# LPC55S06 register map
Vendor: nxp.com; File version: 1.0
CPU: CM33 r2p0, little endian, MPU, FPU, VTOR, 3 interrupt priority bits
Registers are 32-bit, read-write, reset 0x0 unless marked. A register's access mark holds for its fields unless they carry their own. Offsets are from the block's base; [hi:lo] are bit positions; {n}, {i} and the like mark numbered series; 'fields as' and 'values as' point back to an identical list.

## FLASH_NMPA
Base 0x0003FC00
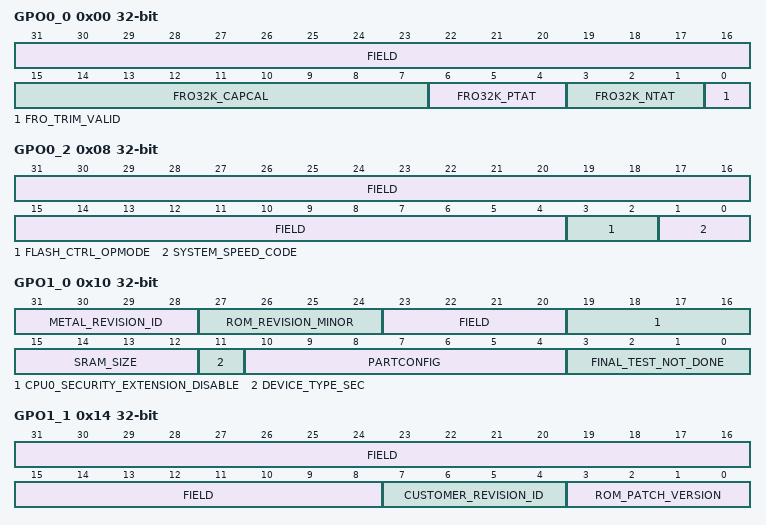
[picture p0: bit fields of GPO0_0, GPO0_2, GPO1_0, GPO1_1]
0x00 GPO0_0 (GPO0 view) — GPO0 register 0 description
  [31:16] FIELD, [15:7] FRO32K_CAPCAL, [6:4] FRO32K_PTAT, [3:1] FRO32K_NTAT, [0] FRO_TRIM_VALID
{0x0+0x10*i} GPO{i}_ARRAY0 (GPO{i} view) (i=0..3) — GPO{i} array description
  [31:0] FIELD
0x04 GPO0_1 (GPO0 view) — GPO0 register 1 description
  [31:0] FIELD
{0x4+0x10*i} GPO{i}_ARRAY1 (GPO{i} view) (i=0..3) — GPO{i} array description
  [31:0] FIELD
0x08 GPO0_2 (GPO0 view) — GPO0 register 2 description
  [31:4] FIELD
  [3:2] FLASH_CTRL_OPMODE — 00 : Delay Line 01 : RCLK (back up clock) 10 : PCLK (back up clock)
  [1:0] SYSTEM_SPEED_CODE — 00 : FRO12MHz 01 : FRO24MHz 10 : FRO48MHz 11 : FRO96MHz
{0x8+0x10*i} GPO{i}_ARRAY2 (GPO{i} view) (i=0..3) — GPO{i} array description
  [31:0] FIELD
0x0C GPO0_3 (GPO0 view) — GPO0 register 3 description
  [31:0] FIELD
{0xC+0x10*i} GPO{i}_ARRAY3 (GPO{i} view) (i=0..3) — GPO{i} array description
  [31:0] FIELD
0x10 GPO1_0 (GPO1 view) — GPO1 register 0 description
  [31:28] METAL_REVISION_ID — METAL REVISION ID[3:0]
  [27:24] ROM_REVISION_MINOR — ROM Revision-Minor [3:0]
  [23:20] FIELD
  [19:16] CPU0_SECURITY_EXTENSION_DISABLE — CPU0_SECURITY_EXTENSION_DISABLE[3:0]: 1010 : CPU0 Security Extension is disabled. All Other values: CPU0 Security Extension is enabled.
  [15:12] SRAM_SIZE — SRAM_SIZE[3:0]: (For Niobe4) 0000 : 320 KB 0001 : 256 KB 0010 : 144 KB 0011 : 80 KB (For Niobe4 Mini) 0100 : 96 KB 0101 : 80 KB 0110 : 64 KB 0111 : 48 KB All others : RESERVED
  [11] DEVICE_TYPE_SEC — Security device type: 0: LPC55xxx (Non Secure Familly) 1: LPC55Sxxx (Secure Familly)
  [10:4] PARTCONFIG — Device type number. (E.g : LPC5569 stored as 69 decimal)
  [3:0] FINAL_TEST_NOT_DONE — FINAL_TEST_NOT_DONE[3:0]: 1010 : Final Test Not Done. All Other values: Final Test Done.
0x14 GPO1_1 (GPO1 view) — GPO1 register 1 description
  [31:8] FIELD
  [7:4] CUSTOMER_REVISION_ID — CUSTOMER REVISION ID[3:0]
  [3:0] ROM_PATCH_VERSION — ROM Patch Version [3:0]
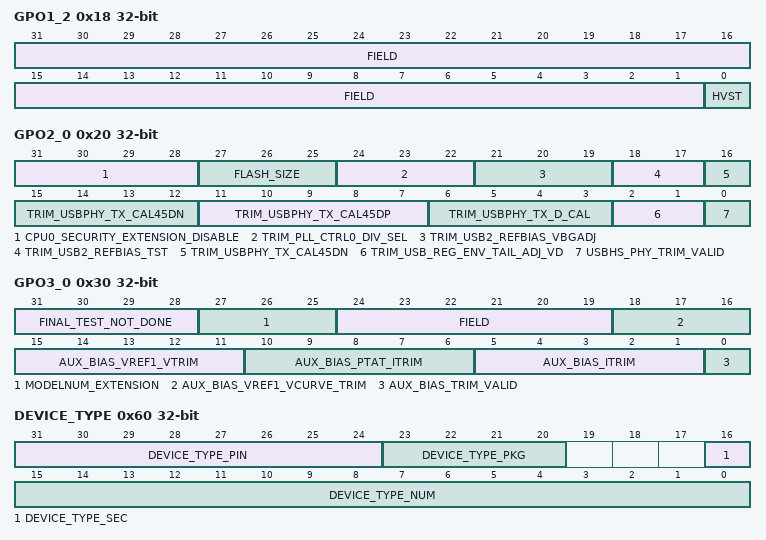
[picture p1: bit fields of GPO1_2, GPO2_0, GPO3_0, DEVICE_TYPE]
0x18 GPO1_2 (GPO1 view) — GPO1 register 2 description
  [31:1] FIELD
  [0] HVST — High Voltage Stress: 0=not done; 1=done.
0x1C GPO1_3 (GPO1 view) — GPO1 register 3 description
  [31:0] FIELD
0x20 GPO2_0 (GPO2 view) — GPO2 register 0 description
  [31:28] CPU0_SECURITY_EXTENSION_DISABLE — CPU0_SECURITY_EXTENSION_DISABLE[3:0]: 1010 : CPU0 Security Extension is disabled. All Other values: CPU0 Security Extension is enabled.
  [27:25] FLASH_SIZE — (For Niobe4) 000 : 640 KB 001 : 512 KB 010 : 256 KB 011 : 128 KB 100 : 0 KB All others : RESERVED (For Niobe4 Mini) FLASH_SIZE[2:0] 000 : 256 KB 001 : 128 KB 010 : 80 KB (reserved) 011 : 64 KB 100 : 0 kB (reserved) All others : RESERVED
  [24:22] TRIM_PLL_CTRL0_DIV_SEL
  [21:19] TRIM_USB2_REFBIAS_VBGADJ
  [18:17] TRIM_USB2_REFBIAS_TST
  [16:12] TRIM_USBPHY_TX_CAL45DN
  [11:7] TRIM_USBPHY_TX_CAL45DP
  [6:3] TRIM_USBPHY_TX_D_CAL
  [2:1] TRIM_USB_REG_ENV_TAIL_ADJ_VD
  [0] USBHS_PHY_TRIM_VALID
{0x20+4i} GPO2_{i} (GPO2 view) (i=1..3) — GPO2 register {i} description
  [31:0] FIELD
0x30 GPO3_0 (GPO3 view) — GPO3 register 0 description
  [31:28] FINAL_TEST_NOT_DONE — FINAL_TEST_NOT_DONE[3:0]: 1010 : Final Test Not Done. All Other values: Final Test Done.
  [27:25] MODELNUM_EXTENSION — ModelNumber extension[2:0]
  [24:19] FIELD
  [18:16] AUX_BIAS_VREF1_VCURVE_TRIM
  [15:11] AUX_BIAS_VREF1_VTRIM
  [10:6] AUX_BIAS_PTAT_ITRIM
  [5:1] AUX_BIAS_ITRIM
  [0] AUX_BIAS_TRIM_VALID
{0x30+4i} GPO3_{i} (GPO3 view) (i=1..3) — GPO3 register {i} description
  [31:0] FIELD
{0x40+4i} GPO_CHECKSUM_{i} (GPO_CHECKSUM view) (i=0..3) — checksum of the GPO data in words {i}
  [31:0] FIELD
{0x40+4i} GPO_CHECKSUM_ARRAY{i} (GPO_CHECKSUM view) (i=0..3) — checksum of the GPO data in words [3:0]
  [31:0] FIELD
{0x50+4i} FINAL_TEST_BATCH_ID_{i} (FINAL_TEST_BATCH_ID view) (i=0..3)
  [31:0] FIELD
{0x50+4i} FINAL_TEST_BATCH_ID_ARRAY{i} (FINAL_TEST_BATCH_ID view) (i=0..3)
  [31:0] FIELD
0x60 DEVICE_TYPE
  [31:24] DEVICE_TYPE_PIN — Number of pins on the package.
  [23:20] DEVICE_TYPE_PKG — Device package type: 0000 : HLQFP 0001 : HTQFP 0010 : HVQFN 0100 : VFBGA 1000 : WLCSP
  [16] DEVICE_TYPE_SEC — Security device type: 0: LPC55xxx (Non Secure Familly) 1: LPC55Sxxx (Secure Familly)
  [15:0] DEVICE_TYPE_NUM — Device type number. (E.g : LPC5569 stored as 5569 decimal)
0x64 FINAL_TEST_PROGRAM_VERSION
  [31:0] PROGRAM_VERSION — PROGRAM_VERSION [xx.yy stored as : 100*x+y]
0x68 FINAL_TEST_DATE
  [31:0] DATE — DATE [stored as : year*10000+month*100+day]
0x6C FINAL_TEST_TIME
  [31:0] TIME — TIME [stored as : hour*10000+minute*100+seconde]
{0x70+4i} UUID_{i} (UUID view) (i=0..3)
  [31:0] FIELD
{0x70+4i} UUID_ARRAY{i} (UUID view) (i=0..3)
  [31:0] FIELD
0x80 WAFER_TEST1_PROGRAM_VERSION
  [31:0] WT1_PROGRAM_VERSION — WT1_PROGRAM_VERSION [xx.yy stored as : 100*x+y]
0x84 WAFER_TEST1_DATE
  [31:0] WT1_DATE — WT1_DATE [stored as : year*10000+month*100+day]
0x88 WAFER_TEST1_TIME
  [31:0] WT1_TIME — WT1_TIME [stored as : hour*10000+minute*100+seconde]
0x90 WAFER_TEST2_PROGRAM_VERSION
  [31:0] WT2_PROGRAM_VERSION — WT2_PROGRAM_VERSION [xx.yy stored as : 100*x+y]
0x94 WAFER_TEST2_DATE
  [31:0] WT2_DATE — WT2_DATE [stored as : year*10000+month*100+day]
0x98 WAFER_TEST2_TIME
  [31:0] WT2_TIME — WT2_TIME [stored as : hour*10000+minute*100+seconde]
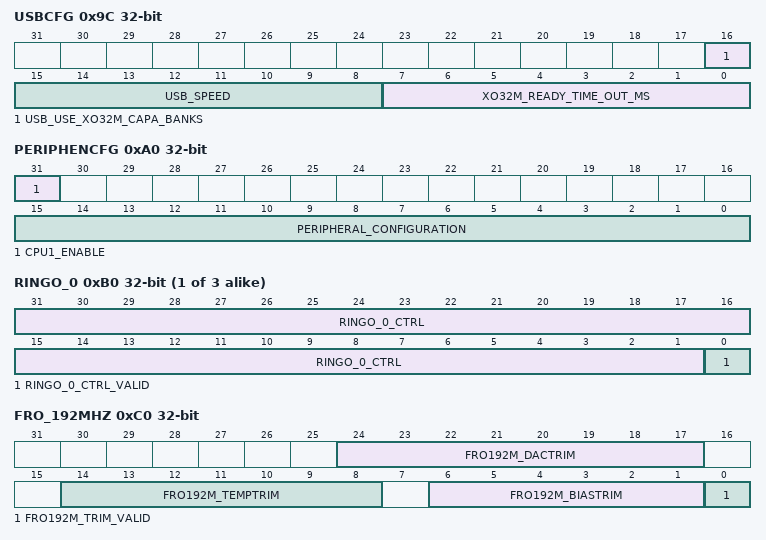
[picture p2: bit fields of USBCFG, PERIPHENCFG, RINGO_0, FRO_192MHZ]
0x9C USBCFG
  [16] USB_USE_XO32M_CAPA_BANKS — Enable the use of Crystal 32 MHz internal Capa Banks during the configuration of the High Speed USB for ISP: 0: Disable Crystal 32 MHz CapaBanks. 1: Enable Crystal 32 MHz CapaBanks.
  [15:8] USB_SPEED — USB_SPEED[7:0]= 0x00 : USB High Speed Module used for ISP 0x01 : USB Full SPeed Module used for ISP 0x02 : Neither USB High Speed module nor USB Full Speed module used for ISP 0x03 - 0xFF : RESERVED
  [7:0] XO32M_READY_TIME_OUT_MS
0xA0 PERIPHENCFG
  [31] CPU1_ENABLE, [15:0] PERIPHERAL_CONFIGURATION
0xA4 RAMSIZECFG
  [31:0] SRAM_CONFIGURATION
0xA8 FLASHSIZECFG
  [31:0] FLASH_CONFIGURATION
{0xB0+4i} RINGO_{i} (i=0..2)
  [31:1] RINGO_{i}_CTRL — To copy RINGO_{i}_CTRL = ANACTRL->RINGO{i}_CTRL[30:0]
  [0] RINGO_{i}_CTRL_VALID — 1: RINGO_{i}_CTRL is valid.
0xC0 FRO_192MHZ
  [24:17] FRO192M_DACTRIM — FRO192M_DACTRIM[7:0].
  [14:8] FRO192M_TEMPTRIM — FRO192M_TEMPTRIM[6:0].
  [6:1] FRO192M_BIASTRIM — FRO192M_BIASTRIM[5:0].
  [0] FRO192M_TRIM_VALID
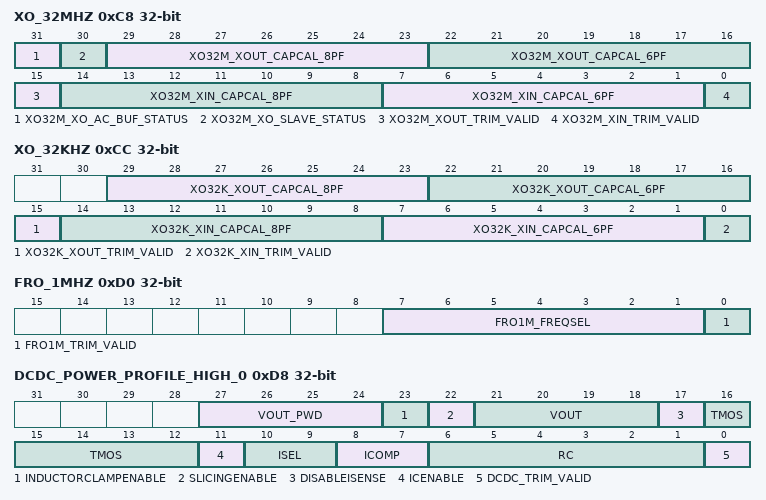
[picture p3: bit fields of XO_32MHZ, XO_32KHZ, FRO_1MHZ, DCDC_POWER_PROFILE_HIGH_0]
0xC8 XO_32MHZ
  [31] XO32M_XO_AC_BUF_STATUS, [30] XO32M_XO_SLAVE_STATUS, [29:23] XO32M_XOUT_CAPCAL_8PF, [22:16] XO32M_XOUT_CAPCAL_6PF, [15] XO32M_XOUT_TRIM_VALID, [14:8] XO32M_XIN_CAPCAL_8PF, [7:1] XO32M_XIN_CAPCAL_6PF, [0] XO32M_XIN_TRIM_VALID
0xCC XO_32KHZ
  [29:23] XO32K_XOUT_CAPCAL_8PF, [22:16] XO32K_XOUT_CAPCAL_6PF, [15] XO32K_XOUT_TRIM_VALID, [14:8] XO32K_XIN_CAPCAL_8PF, [7:1] XO32K_XIN_CAPCAL_6PF, [0] XO32K_XIN_TRIM_VALID
0xD0 FRO_1MHZ
  [7:1] FRO1M_FREQSEL — Frequency trimming bits.
  [0] FRO1M_TRIM_VALID
0xD8 DCDC_POWER_PROFILE_HIGH_0 (DCDC_POWER_PROFILE_HIGH view)
  [27:24] VOUT_PWD — Set output regulation voltage during Deep Sleep.
  [23] INDUCTORCLAMPENABLE — Enable shorting of Inductor during PFM idle time.
  [22] SLICINGENABLE — Enable staggered switching of power switches.
  [21:18] VOUT — Set output regulation voltage.
  [17] DISABLEISENSE — Disable Current sensing.
  [16:12] TMOS — One-shot generator reference current trimming signal.
  [11] ICENABLE — Selection of auto scaling of COT period with variations in VDD.
  [10:9] ISEL — Alter Internal biasing currents.
  [8:7] ICOMP — Select the type of ZCD comparator.
  [6:1] RC — Constant On-Time calibration.
  [0] DCDC_TRIM_VALID — DCDC is trimed.
0xD8 DCDC_POWER_PROFILE_HIGH_ARRAY0 (DCDC_POWER_PROFILE_HIGH view)
  [31:0] FIELD
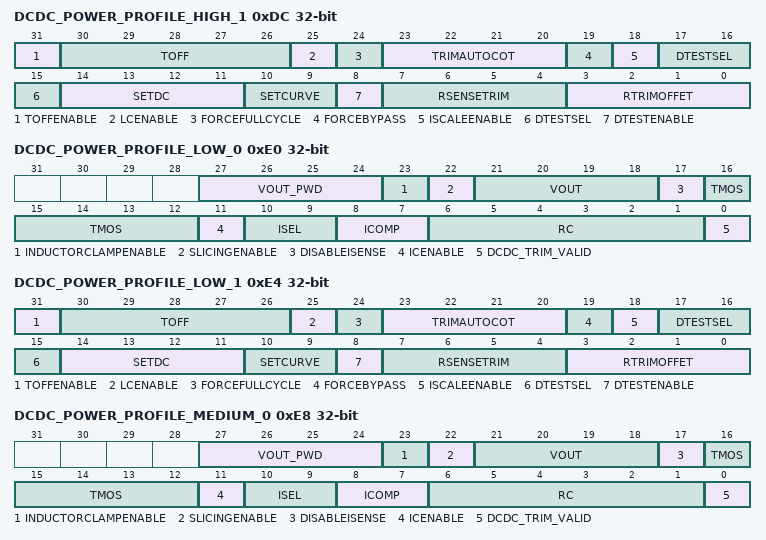
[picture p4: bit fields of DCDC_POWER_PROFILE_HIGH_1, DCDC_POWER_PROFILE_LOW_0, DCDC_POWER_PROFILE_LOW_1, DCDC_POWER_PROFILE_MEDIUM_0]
0xDC DCDC_POWER_PROFILE_HIGH_1 (DCDC_POWER_PROFILE_HIGH view)
  [31] TOFFENABLE — Enable Constant Off-Time feature.
  [30:26] TOFF — Constant Off-Time calibration input.
  [25] LCENABLE — Change the range of the peak detector of current inside the inductor.
  [24] FORCEFULLCYCLE — Force full PFM PMOS and NMOS cycle.
  [23:20] TRIMAUTOCOT — Change the scaling ratio of the feedforward compensation.
  [19] FORCEBYPASS — Force bypass mode.
  [18] ISCALEENABLE — Modify COT behavior.
  [17:15] DTESTSEL — Select the output signal for test.
  [14:11] SETDC — Bandgap calibration parameter.
  [10:9] SETCURVE — Bandgap calibration parameter.
  [8] DTESTENABLE — Enable Digital test signals.
  [7:4] RSENSETRIM — Adjust Max inductor peak current limiting.
  [3:0] RTRIMOFFET — Adjust the offset voltage of BJT based comparator.
0xDC DCDC_POWER_PROFILE_HIGH_ARRAY1 (DCDC_POWER_PROFILE_HIGH view)
  [31:0] FIELD
0xE0 DCDC_POWER_PROFILE_LOW_0 (DCDC_POWER_PROFILE_LOW view)
  fields as DCDC_POWER_PROFILE_HIGH_0
0xE0 DCDC_POWER_PROFILE_LOW_ARRAY0 (DCDC_POWER_PROFILE_LOW view)
  [31:0] FIELD
0xE4 DCDC_POWER_PROFILE_LOW_1 (DCDC_POWER_PROFILE_LOW view)
  fields as DCDC_POWER_PROFILE_HIGH_1
0xE4 DCDC_POWER_PROFILE_LOW_ARRAY1 (DCDC_POWER_PROFILE_LOW view)
  [31:0] FIELD
0xE8 DCDC_POWER_PROFILE_MEDIUM_0 (DCDC_POWER_PROFILE_MEDIUM view)
  fields as DCDC_POWER_PROFILE_HIGH_0
0xE8 DCDC_POWER_PROFILE_MEDIUM_ARRAY0 (DCDC_POWER_PROFILE_MEDIUM view)
  [31:0] FIELD
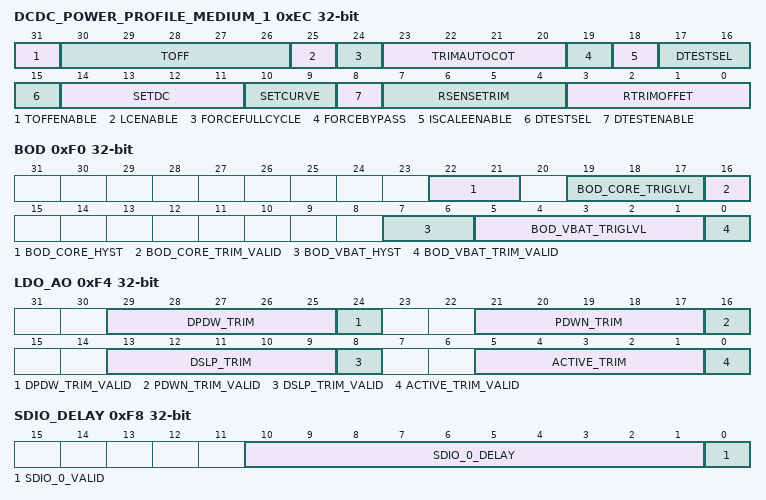
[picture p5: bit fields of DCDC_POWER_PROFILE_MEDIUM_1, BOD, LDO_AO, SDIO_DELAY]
0xEC DCDC_POWER_PROFILE_MEDIUM_1 (DCDC_POWER_PROFILE_MEDIUM view)
  fields as DCDC_POWER_PROFILE_HIGH_1
0xEC DCDC_POWER_PROFILE_MEDIUM_ARRAY1 (DCDC_POWER_PROFILE_MEDIUM view)
  [31:0] FIELD
0xF0 BOD
  [22:21] BOD_CORE_HYST, [19:17] BOD_CORE_TRIGLVL, [16] BOD_CORE_TRIM_VALID, [7:6] BOD_VBAT_HYST, [5:1] BOD_VBAT_TRIGLVL, [0] BOD_VBAT_TRIM_VALID
0xF4 LDO_AO
  [29:25] DPDW_TRIM, [24] DPDW_TRIM_VALID, [21:17] PDWN_TRIM, [16] PDWN_TRIM_VALID, [13:9] DSLP_TRIM, [8] DSLP_TRIM_VALID, [5:1] ACTIVE_TRIM, [0] ACTIVE_TRIM_VALID
0xF8 SDIO_DELAY
  [10:1] SDIO_0_DELAY — SDIO_0_DELAY (unit: 100 ps).
  [0] SDIO_0_VALID
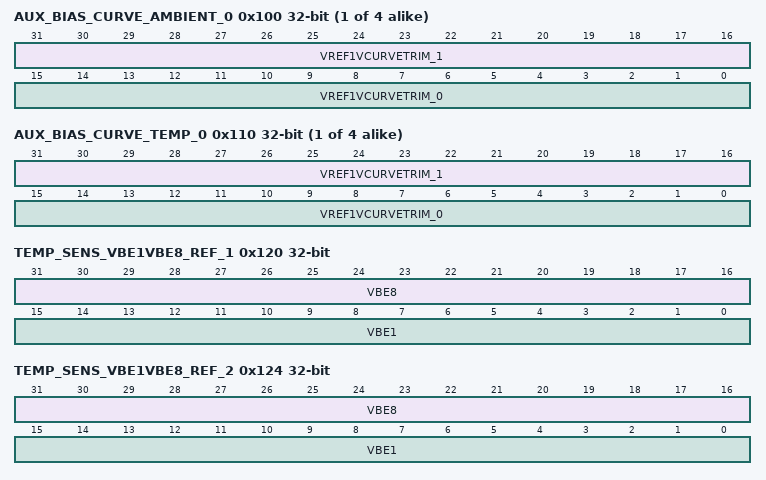
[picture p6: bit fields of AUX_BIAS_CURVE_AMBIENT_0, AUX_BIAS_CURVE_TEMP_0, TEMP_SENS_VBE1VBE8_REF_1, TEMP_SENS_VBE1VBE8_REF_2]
{0x100+4i} AUX_BIAS_CURVE_AMBIENT_{i} (AUX_BIAS_CURVE_AMBIENT view) (i=0..3)
  [31:16] VREF1VCURVETRIM_{2i+1} — VREF1VCURVETRIM_{2i+1} (unit: 100uV)
  [15:0] VREF1VCURVETRIM_{2i} — VREF1VCURVETRIM_{2i} (unit: 100uV)
{0x100+4i} AUX_BIAS_CURVE_AMBIENT_ARRAY{i} (AUX_BIAS_CURVE_AMBIENT view) (i=0..3) — Aux Bias Curve Ambient (30degC)
  [31:0] FIELD
{0x110+4i} AUX_BIAS_CURVE_TEMP_{i} (AUX_BIAS_CURVE_TEMP view) (i=0..3)
  fields as AUX_BIAS_CURVE_AMBIENT_0
{0x110+4i} AUX_BIAS_CURVE_TEMP_ARRAY{i} (AUX_BIAS_CURVE_TEMP view) (i=0..3) — Aux Bias Curve TEMP (105degC)
  [31:0] FIELD
0x120 TEMP_SENS_VBE1VBE8_REF_1
  [31:16] VBE8, [15:0] VBE1
0x124 TEMP_SENS_VBE1VBE8_REF_2
  [31:16] VBE8, [15:0] VBE1
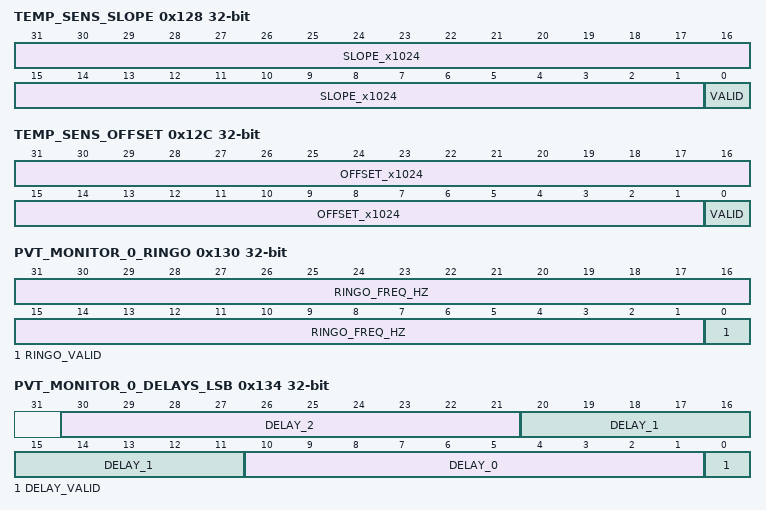
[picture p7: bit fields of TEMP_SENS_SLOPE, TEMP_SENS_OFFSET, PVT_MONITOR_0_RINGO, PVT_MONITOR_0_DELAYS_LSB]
0x128 TEMP_SENS_SLOPE
  [31:1] SLOPE_x1024 — SLOPE_x1024[30:0]
  [0] VALID
0x12C TEMP_SENS_OFFSET
  [31:1] OFFSET_x1024 — OFFSET_x1024[30:0]
  [0] VALID
{0x130+4i} PVT_MONITOR_0_ARRAY{i} (PVT_MONITOR_0 view) (i=0..2)
  [31:0] FIELD
0x130 PVT_MONITOR_0_RINGO (PVT_MONITOR_0 view)
  [31:1] RINGO_FREQ_HZ, [0] RINGO_VALID
0x134 PVT_MONITOR_0_DELAYS_LSB (PVT_MONITOR_0 view)
  [30:21] DELAY_2 — Delay in us.
  [20:11] DELAY_1 — Delay in us.
  [10:1] DELAY_0 — Delay in us.
  [0] DELAY_VALID
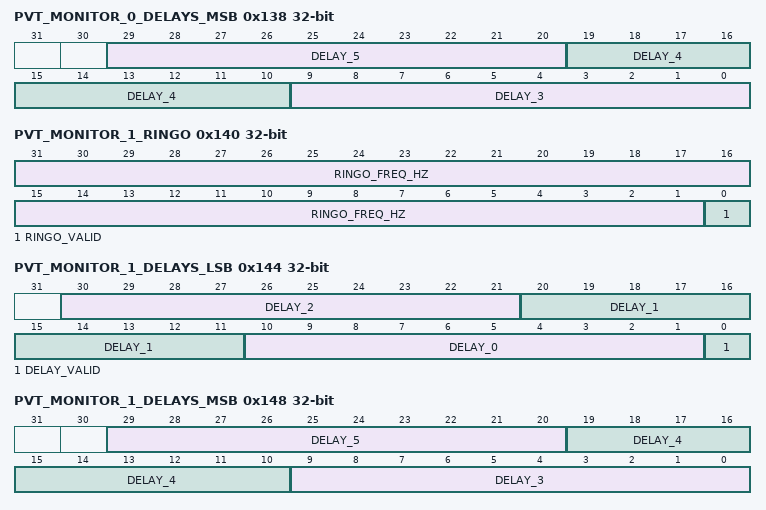
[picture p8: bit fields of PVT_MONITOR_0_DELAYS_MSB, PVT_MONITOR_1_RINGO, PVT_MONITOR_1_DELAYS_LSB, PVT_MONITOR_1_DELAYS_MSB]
0x138 PVT_MONITOR_0_DELAYS_MSB (PVT_MONITOR_0 view)
  [29:20] DELAY_5 — Delay in us.
  [19:10] DELAY_4 — Delay in us.
  [9:0] DELAY_3 — Delay in us.
{0x140+4i} PVT_MONITOR_1_ARRAY{i} (PVT_MONITOR_1 view) (i=0..2)
  [31:0] FIELD
0x140 PVT_MONITOR_1_RINGO (PVT_MONITOR_1 view)
  [31:1] RINGO_FREQ_HZ, [0] RINGO_VALID
0x144 PVT_MONITOR_1_DELAYS_LSB (PVT_MONITOR_1 view)
  fields as PVT_MONITOR_0_DELAYS_LSB
0x148 PVT_MONITOR_1_DELAYS_MSB (PVT_MONITOR_1 view)
  fields as PVT_MONITOR_0_DELAYS_MSB
{0x14C+4i} NXP_DEVICE_PRIVATE_KEY[{i}] (i=0..12)
  [31:0] FIELD
{0x180+4i} NXP_DEVICE_CERTIFICATE_0[{i}] (i=0..3) — NXP Device Certificate (ECDSA_sign - r[255:128])
  [31:0] FIELD
{0x190+4i} NXP_DEVICE_CERTIFICATE_1[{i}] (i=0..3) — NXP Device Certificate (ECDSA_sign - r[127:0])
  [31:0] FIELD
{0x1A0+4i} NXP_DEVICE_CERTIFICATE_2[{i}] (i=0..3) — NXP Device Certificate (ECDSA_sign - s[255:128])
  [31:0] FIELD
{0x1B0+4i} NXP_DEVICE_CERTIFICATE_3[{i}] (i=0..3) — NXP Device Certificate (ECDSA_sign - s[127:0])
  [31:0] FIELD
{0x1C0+4i} SHA256_DIGEST[{i}] (i=0..7) — SHA-256 DIGEST (9EC00 - 9FDBC) ROM Patch Area + NXP Area (IMPORTANT NOTE: Pages used for Repair (N-8 to N-3) are excluded from the computation) SHA256_DIGEST0 for DIGEST[31:0] SHA256_DIGEST1 for DIGEST[63:32] SHA256_DIGEST2 for DIGEST[95:64] SHA256_DIGEST3 for DIGEST[127:96] SHA256_DIGEST4 for DIGEST[159:128] SHA256_DIGEST5 for DIGEST[191:160] SHA256_DIGEST6 for DIGEST[223:192] SHA256_DIGEST7 for DIGEST[255:224]
  [31:0] FIELD
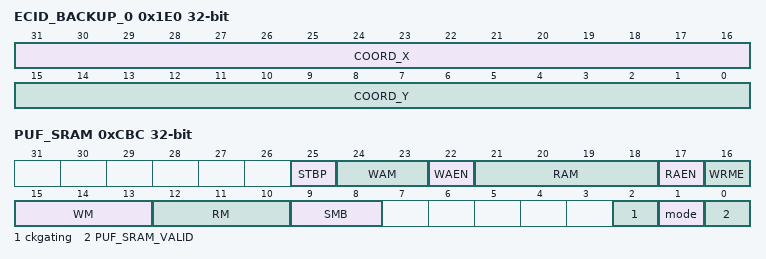
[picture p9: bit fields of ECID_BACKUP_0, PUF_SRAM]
0x1E0 ECID_BACKUP_0 (ECID_BACKUP view)
  [31:16] COORD_X, [15:0] COORD_Y
{0x1E0+4i} ECID_BACKUP_ARRAY{i} (ECID_BACKUP view) (i=0..3) — ECID backup (the original is in page n-1)
  [31:0] FIELD
0x1E4 ECID_BACKUP_1 (ECID_BACKUP view)
  [7:0] WAFER
0x1E8 ECID_BACKUP_2 (ECID_BACKUP view)
  [31:0] LOTID_LSB
0x1EC ECID_BACKUP_3 (ECID_BACKUP view)
  [31:0] LOTID_MSB
{0x1F0+4i} CHECKSUM[{i}] (i=0..3) — Checksum of the whole page
0xCAC DIS_ROM_HIDING
  [31:0] DIS_ROM_HIDING — When 0x3CC35AA5 ROM hiding feture is disabled. All other values critical ROM is hidden.
0xCBC PUF_SRAM
  [25] STBP
  [24:23] WAM — SRAM Write Assist settings
  [22] WAEN — SRAM Write Assist Enable
  [21:18] RAM — SRAM Read Assist settings
  [17] RAEN — SRAM Read Assist Enable
  [16] WRME — Write read margin enable.
  [15:13] WM — Write Margin control settings.
  [12:10] RM — Read Margin control settings.
  [9:8] SMB — Source Biasing voltage.
    0=LOW (Low leakage.); 1=MEDIUM (Medium leakage.); 2=HIGHEST (Highest leakage.); 3=DISABLE
  [2] ckgating — PUF SRAM Clock Gating control
  [1] mode — PUF SRAM Controller operating mode
  [0] PUF_SRAM_VALID — 1: PUF_SRAM is valid.
